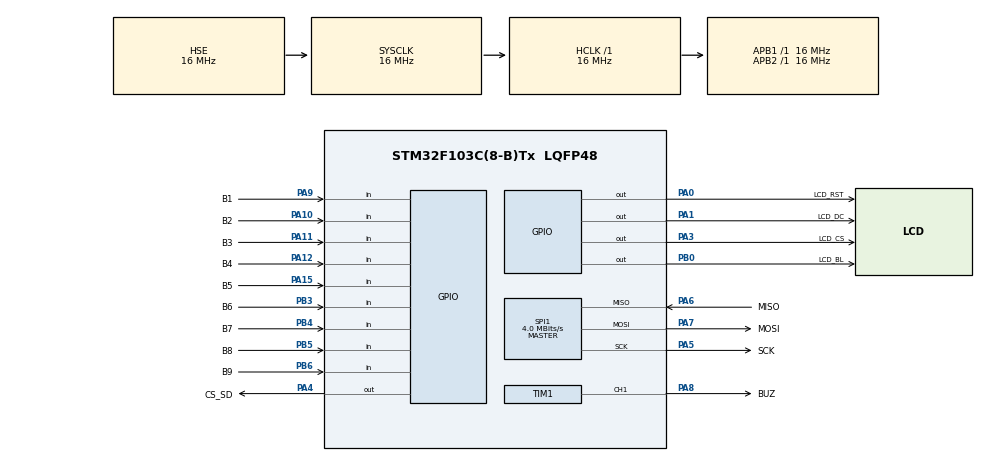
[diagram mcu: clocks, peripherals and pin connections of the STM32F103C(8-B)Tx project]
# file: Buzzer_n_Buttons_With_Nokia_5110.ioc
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Mcu.Family=STM32F1
Mcu.Name=STM32F103C(8-B)Tx
Mcu.Package=LQFP48
NVIC.PriorityGroup=NVIC_PRIORITYGROUP_4
PA0-WKUP.GPIO_Label=LCD_RST
PA0-WKUP.Signal=GPIO_Output
PA1.GPIO_Label=LCD_DC
PA1.Signal=GPIO_Output
PA10.GPIO_Label=B2
PA10.GPIO_PuPd=GPIO_PULLDOWN
PA10.Signal=GPIO_Input
PA11.GPIO_Label=B3
PA11.GPIO_PuPd=GPIO_PULLDOWN
PA11.Signal=GPIO_Input
PA12.GPIO_Label=B4
PA12.GPIO_PuPd=GPIO_PULLDOWN
PA12.Signal=GPIO_Input
PA13.Mode=Serial_Wire
PA13.Signal=SYS_JTMS-SWDIO
PA14.Mode=Serial_Wire
PA14.Signal=SYS_JTCK-SWCLK
PA15.GPIO_Label=B5
PA15.GPIO_PuPd=GPIO_PULLDOWN
PA15.Signal=GPIO_Input
PA3.GPIO_Label=LCD_CS
PA3.Signal=GPIO_Output
PA4.GPIO_Label=CS_SD
PA4.Signal=GPIO_Output
PA5.GPIO_Label=SCK
PA5.Mode=Full_Duplex_Master
PA5.Signal=SPI1_SCK
PA6.GPIO_Label=MISO
PA6.Mode=Full_Duplex_Master
PA6.Signal=SPI1_MISO
PA7.GPIO_Label=MOSI
PA7.Mode=Full_Duplex_Master
PA7.Signal=SPI1_MOSI
PA8.GPIO_Label=BUZ
PA8.Signal=S_TIM1_CH1
PA9.GPIO_Label=B1
PA9.GPIO_PuPd=GPIO_PULLDOWN
PA9.Signal=GPIO_Input
PB0.GPIO_Label=LCD_BL
PB0.GPIO_PuPd=GPIO_NOPULL
PB0.Signal=GPIO_Output
PB3.GPIO_Label=B6
PB3.GPIO_PuPd=GPIO_PULLDOWN
PB3.Signal=GPIO_Input
PB4.GPIO_Label=B7
PB4.GPIO_PuPd=GPIO_PULLDOWN
PB4.Signal=GPIO_Input
PB5.GPIO_Label=B8
PB5.GPIO_PuPd=GPIO_PULLDOWN
PB5.Signal=GPIO_Input
PB6.GPIO_Label=B9
PB6.GPIO_PuPd=GPIO_PULLDOWN
PB6.Signal=GPIO_Input
PD0-OSC_IN.Mode=HSE-External-Oscillator
PD0-OSC_IN.Signal=RCC_OSC_IN
PD1-OSC_OUT.Mode=HSE-External-Oscillator
PD1-OSC_OUT.Signal=RCC_OSC_OUT
ProjectManager.HeapSize=0x200
ProjectManager.StackSize=0x400
ProjectManager.TargetToolchain=STM32CubeIDE
RCC.AHBFreq_Value=16000000
RCC.APB1Freq_Value=16000000
RCC.APB1TimFreq_Value=16000000
RCC.APB2Freq_Value=16000000
RCC.APB2TimFreq_Value=16000000
RCC.HCLKFreq_Value=16000000
RCC.HSE_VALUE=16000000
RCC.SYSCLKFreq_VALUE=16000000
RCC.SYSCLKSource=RCC_SYSCLKSOURCE_HSE
SH.S_TIM1_CH1.0=TIM1_CH1,PWM Generation1 CH1
SPI1.BaudRatePrescaler=SPI_BAUDRATEPRESCALER_4
SPI1.CalculateBaudRate=4.0 MBits/s
SPI1.Direction=SPI_DIRECTION_2LINES
SPI1.Mode=SPI_MODE_MASTER
SPI1.VirtualType=VM_MASTER
TIM1.Channel-PWM\ Generation1\ CH1=TIM_CHANNEL_1
TIM1.Period=250-1
TIM1.Prescaler=16-1
VP_TIM1_VS_ClockSourceINT.Mode=Internal
board=custom

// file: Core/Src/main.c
/* USER CODE BEGIN Header */
/**
  ******************************************************************************
  * @file           : main.c
  * @brief          : Main program body
  ******************************************************************************
  * @attention
  *
  * Copyright (c) 2026 STMicroelectronics.
  * All rights reserved.
  *
  * This software is licensed under terms that can be found in the LICENSE file
  * in the root directory of this software component.
  * If no LICENSE file comes with this software, it is provided AS-IS.
  *
  ******************************************************************************
  */
/* USER CODE END Header */
#include "main.h"

/* USER CODE BEGIN Includes */

#include "app.h"
#include "string.h"

/* USER CODE END Includes */

SPI_HandleTypeDef hspi1;

TIM_HandleTypeDef htim1;

void SystemClock_Config(void);
static void MX_GPIO_Init(void);
static void MX_SPI1_Init(void);
static void MX_TIM1_Init(void);

int main(void)
{

  /* MCU Configuration--------------------------------------------------------*/

  /* Reset of all peripherals, Initializes the Flash interface and the Systick. */
  HAL_Init();

  /* Configure the system clock */
  SystemClock_Config();

  /* Initialize all configured peripherals */
  MX_GPIO_Init();
  MX_SPI1_Init();
  MX_TIM1_Init();
  /* USER CODE BEGIN 2 */

  Display_Init();
  Buttons_Init();
  Buzzer_Init();

//  uint8_t test[84];
//
//  memset(test, 0xFF, 84);
//
//  for (uint8_t p = 0; p < 6; p++)
//  {
//      LCD_PCD8544_write_bytes(&gLcdScreen, p, 0, test, 84);
//  }

  /* USER CODE END 2 */

  /* Infinite loop */
  while (1)
  {

    /* USER CODE BEGIN 3 */

	  Buttons_Update();
	  Buzzer_Update();

	  ButtonId_t btn = App_GetButtonPressed();
	  if (btn != BTN_COUNT)
	  {
		  App_OnButtonPressed(btn);
	  }
  }
  /* USER CODE END 3 */
}

void SystemClock_Config(void)
{
  RCC_OscInitTypeDef RCC_OscInitStruct = {0};
  RCC_ClkInitTypeDef RCC_ClkInitStruct = {0};

  /** Initializes the RCC Oscillators according to the specified parameters
  * in the RCC_OscInitTypeDef structure.
  */
  RCC_OscInitStruct.OscillatorType = RCC_OSCILLATORTYPE_HSE;
  RCC_OscInitStruct.HSEState = RCC_HSE_ON;
  RCC_OscInitStruct.PLL.PLLState = RCC_PLL_NONE;
  if (HAL_RCC_OscConfig(&RCC_OscInitStruct) != HAL_OK)
  {
    Error_Handler();
  }

  /** Initializes the CPU, AHB and APB buses clocks
  */
  RCC_ClkInitStruct.ClockType = RCC_CLOCKTYPE_HCLK|RCC_CLOCKTYPE_SYSCLK
                              |RCC_CLOCKTYPE_PCLK1|RCC_CLOCKTYPE_PCLK2;
  RCC_ClkInitStruct.SYSCLKSource = RCC_SYSCLKSOURCE_HSE;
  RCC_ClkInitStruct.AHBCLKDivider = RCC_SYSCLK_DIV1;
  RCC_ClkInitStruct.APB1CLKDivider = RCC_HCLK_DIV1;
  RCC_ClkInitStruct.APB2CLKDivider = RCC_HCLK_DIV1;

  if (HAL_RCC_ClockConfig(&RCC_ClkInitStruct, FLASH_LATENCY_0) != HAL_OK)
  {
    Error_Handler();
  }
}

static void MX_SPI1_Init(void)
{

  /* SPI1 parameter configuration*/
  hspi1.Instance = SPI1;
  hspi1.Init.Mode = SPI_MODE_MASTER;
  hspi1.Init.Direction = SPI_DIRECTION_2LINES;
  hspi1.Init.DataSize = SPI_DATASIZE_8BIT;
  hspi1.Init.CLKPolarity = SPI_POLARITY_LOW;
  hspi1.Init.CLKPhase = SPI_PHASE_1EDGE;
  hspi1.Init.NSS = SPI_NSS_SOFT;
  hspi1.Init.BaudRatePrescaler = SPI_BAUDRATEPRESCALER_16;
  hspi1.Init.FirstBit = SPI_FIRSTBIT_MSB;
  hspi1.Init.TIMode = SPI_TIMODE_DISABLE;
  hspi1.Init.CRCCalculation = SPI_CRCCALCULATION_DISABLE;
  hspi1.Init.CRCPolynomial = 10;
  if (HAL_SPI_Init(&hspi1) != HAL_OK)
  {
    Error_Handler();
  }

}

static void MX_TIM1_Init(void)
{

  TIM_ClockConfigTypeDef sClockSourceConfig = {0};
  TIM_MasterConfigTypeDef sMasterConfig = {0};
  TIM_OC_InitTypeDef sConfigOC = {0};
  TIM_BreakDeadTimeConfigTypeDef sBreakDeadTimeConfig = {0};

  htim1.Instance = TIM1;
  htim1.Init.Prescaler = 16-1;
  htim1.Init.CounterMode = TIM_COUNTERMODE_UP;
  htim1.Init.Period = 250-1;
  htim1.Init.ClockDivision = TIM_CLOCKDIVISION_DIV1;
  htim1.Init.RepetitionCounter = 0;
  htim1.Init.AutoReloadPreload = TIM_AUTORELOAD_PRELOAD_DISABLE;
  if (HAL_TIM_Base_Init(&htim1) != HAL_OK)
  {
    Error_Handler();
  }
  sClockSourceConfig.ClockSource = TIM_CLOCKSOURCE_INTERNAL;
  if (HAL_TIM_ConfigClockSource(&htim1, &sClockSourceConfig) != HAL_OK)
  {
    Error_Handler();
  }
  if (HAL_TIM_PWM_Init(&htim1) != HAL_OK)
  {
    Error_Handler();
  }
  sMasterConfig.MasterOutputTrigger = TIM_TRGO_RESET;
  sMasterConfig.MasterSlaveMode = TIM_MASTERSLAVEMODE_DISABLE;
  if (HAL_TIMEx_MasterConfigSynchronization(&htim1, &sMasterConfig) != HAL_OK)
  {
    Error_Handler();
  }
  sConfigOC.OCMode = TIM_OCMODE_PWM1;
  sConfigOC.Pulse = 215;
  sConfigOC.OCPolarity = TIM_OCPOLARITY_HIGH;
  sConfigOC.OCNPolarity = TIM_OCNPOLARITY_HIGH;
  sConfigOC.OCFastMode = TIM_OCFAST_DISABLE;
  sConfigOC.OCIdleState = TIM_OCIDLESTATE_RESET;
  sConfigOC.OCNIdleState = TIM_OCNIDLESTATE_RESET;
  if (HAL_TIM_PWM_ConfigChannel(&htim1, &sConfigOC, TIM_CHANNEL_1) != HAL_OK)
  {
    Error_Handler();
  }
  sBreakDeadTimeConfig.OffStateRunMode = TIM_OSSR_DISABLE;
  sBreakDeadTimeConfig.OffStateIDLEMode = TIM_OSSI_DISABLE;
  sBreakDeadTimeConfig.LockLevel = TIM_LOCKLEVEL_OFF;
  sBreakDeadTimeConfig.DeadTime = 0;
  sBreakDeadTimeConfig.BreakState = TIM_BREAK_DISABLE;
  sBreakDeadTimeConfig.BreakPolarity = TIM_BREAKPOLARITY_HIGH;
  sBreakDeadTimeConfig.AutomaticOutput = TIM_AUTOMATICOUTPUT_DISABLE;
  if (HAL_TIMEx_ConfigBreakDeadTime(&htim1, &sBreakDeadTimeConfig) != HAL_OK)
  {
    Error_Handler();
  }
  HAL_TIM_MspPostInit(&htim1);

}

static void MX_GPIO_Init(void)
{
  GPIO_InitTypeDef GPIO_InitStruct = {0};

  /* GPIO Ports Clock Enable */
  __HAL_RCC_GPIOD_CLK_ENABLE();
  __HAL_RCC_GPIOA_CLK_ENABLE();
  __HAL_RCC_GPIOB_CLK_ENABLE();

  /*Configure GPIO pin Output Level */
  HAL_GPIO_WritePin(GPIOA, LCD_RST_Pin|LCD_DC_Pin|LCD_CS_Pin|CS_SD_Pin, GPIO_PIN_RESET);

  /*Configure GPIO pin Output Level */
  HAL_GPIO_WritePin(LCD_BL_GPIO_Port, LCD_BL_Pin, GPIO_PIN_RESET);

  /*Configure GPIO pins : LCD_RST_Pin LCD_DC_Pin LCD_CS_Pin CS_SD_Pin */
  GPIO_InitStruct.Pin = LCD_RST_Pin|LCD_DC_Pin|LCD_CS_Pin|CS_SD_Pin;
  GPIO_InitStruct.Mode = GPIO_MODE_OUTPUT_PP;
  GPIO_InitStruct.Pull = GPIO_NOPULL;
  GPIO_InitStruct.Speed = GPIO_SPEED_FREQ_LOW;
  HAL_GPIO_Init(GPIOA, &GPIO_InitStruct);

  /*Configure GPIO pin : LCD_BL_Pin */
  GPIO_InitStruct.Pin = LCD_BL_Pin;
  GPIO_InitStruct.Mode = GPIO_MODE_OUTPUT_PP;
  GPIO_InitStruct.Pull = GPIO_NOPULL;
  GPIO_InitStruct.Speed = GPIO_SPEED_FREQ_LOW;
  HAL_GPIO_Init(LCD_BL_GPIO_Port, &GPIO_InitStruct);

  /*Configure GPIO pins : B1_Pin B2_Pin B3_Pin B4_Pin
                           B5_Pin */
  GPIO_InitStruct.Pin = B1_Pin|B2_Pin|B3_Pin|B4_Pin
                          |B5_Pin;
  GPIO_InitStruct.Mode = GPIO_MODE_INPUT;
  GPIO_InitStruct.Pull = GPIO_PULLDOWN;
  HAL_GPIO_Init(GPIOA, &GPIO_InitStruct);

  /*Configure GPIO pins : B6_Pin B7_Pin B8_Pin B9_Pin */
  GPIO_InitStruct.Pin = B6_Pin|B7_Pin|B8_Pin|B9_Pin;
  GPIO_InitStruct.Mode = GPIO_MODE_INPUT;
  GPIO_InitStruct.Pull = GPIO_PULLDOWN;
  HAL_GPIO_Init(GPIOB, &GPIO_InitStruct);

}

void Error_Handler(void)
{
  __disable_irq();
  while (1)
  {
  }
}
